# MB9AF12xL register map
File version: 1.0
CPU: 
Registers are 8-bit, read-write, reset 0x0 unless marked. A register's access mark holds for its fields unless they carry their own. Offsets are from the block's base; lines under a group give offsets from that group; [hi:lo] are bit positions; {n}, {i} and the like mark numbered series; 'fields as' and 'values as' point back to an identical list; <NAME> marks a mode.

## Memory map
0x40000000 FLASH_IF blocks up to offset 0xC — peripheral FLASH_IF
0x40000200 UNIQUE_ID size 0x4 — peripheral UNIQUE_ID
0x40010000 CRG size 0x1 — peripheral CRG
0x40011000 HWWDT size 0x4 — peripheral HWWDT
0x40012000 SWWDT size 0x4 — peripheral SWWDT
0x40015000 DTIM size 0x1C — peripheral DTIM
0x40020000 MFT0 size 0x2 — peripheral MFT0
0x40024000 MFT_PPG size 0x2 — peripheral MFT_PPG
0x40025000 BT0 size 0x2 — peripheral BT0
0x40025040 BT1 size 0x2 — peripheral BT0
0x40025080 BT2 size 0x2 — peripheral BT0
0x400250C0 BT3 size 0x2 — peripheral BT0
0x40025100 BTIOSEL03 size 0x2 — peripheral BTIOSEL03
0x40025200 BT4 size 0x2 — peripheral BT0
0x40025240 BT5 size 0x2 — peripheral BT0
0x40025280 BT6 size 0x2 — peripheral BT0
0x400252C0 BT7 size 0x2 — peripheral BT0
0x40025300 BTIOSEL47 size 0x2 — peripheral BTIOSEL47
0x40025F00 SBSSR blocks up to offset 0xFE — peripheral SBSSR
0x40027000 ADC0 size 0x2 — peripheral ADC0
0x40028000 DAC size 0x3 — peripheral DAC
0x4002E000 CRTRIM size 0x1 — peripheral CRTRIM
0x40030000 EXTI size 0x4 — peripheral EXTI
0x40031000 INTREQ size 0x4 — peripheral INTREQ
0x40033000 GPIO size 0x740 — peripheral GPIO
0x40035000 LVD size 0x2 — peripheral LVD
0x40035100 DS size 0x1 — peripheral DS
0x40038000 MFS0 size 0x2 — peripheral MFS0
0x40038100 MFS1 size 0x2 — peripheral MFS0
0x40038300 MFS3 size 0x2 — peripheral MFS0
0x40038500 MFS5 size 0x2 — peripheral MFS0
0x4003B000 RTC size 0x13 — peripheral RTC

## Interrupts
0 CSV (CRG)
1 SWDT (SWWDT)
2 LVD
3 WFG (MFT0)
4 EXTINT0_7 (EXTI)
5 EXTINT8_23 (EXTI)
6 DTIM_QDU (DTIM)
7 MFS0RX (MFS0)
8 MFS0TX (MFS0)
9 MFS1RX (MFS1)
10 MFS1TX (MFS1)
13 MFS3RX (MFS3)
14 MFS3TX (MFS3)
17 MFS5RX (MFS5)
18 MFS5TX (MFS5)
23 PPG (MFT_PPG)
24 OSC_PLL_WC (CRG)
25 ADC0
28 FRTIM (MFT0)
29 INCAP (MFT0)
30 OUTCOMP (MFT0)
31 BTIM0_7 (BT{n} (n=0..7))

## FLASH_IF — peripheral FLASH_IF
Base 0x40000000
0x04 FRWTR 32-bit reset 0x2
  [1:0] RWT
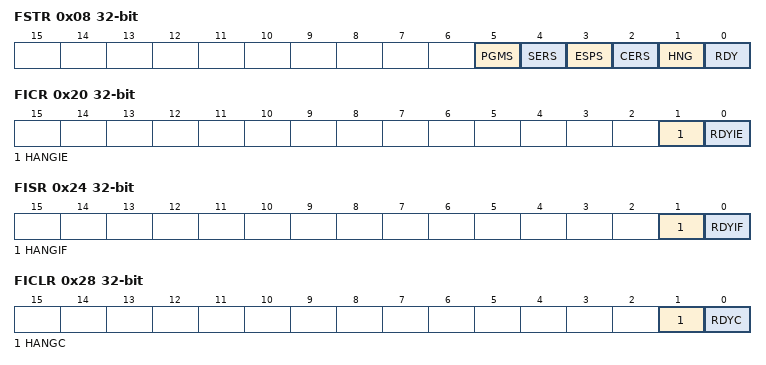
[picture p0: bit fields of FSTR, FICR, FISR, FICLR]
0x08 FSTR 32-bit ro
  [5] PGMS, [4] SERS, [3] ESPS, [2] CERS, [1] HNG, [0] RDY
0x20 FICR 32-bit
  [1] HANGIE, [0] RDYIE
0x24 FISR 32-bit
  [1] HANGIF, [0] RDYIF
0x28 FICLR 32-bit wo
  [1] HANGC rw, [0] RDYC rw
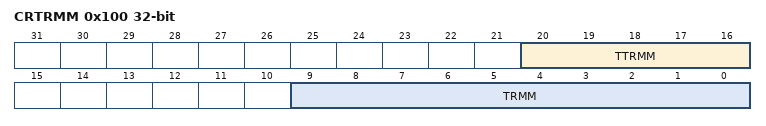
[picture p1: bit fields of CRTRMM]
0x100 CRTRMM 32-bit ro reset not defined
  [20:16] TTRMM, [9:0] TRMM

## UNIQUE_ID — peripheral UNIQUE_ID
Base 0x40000200
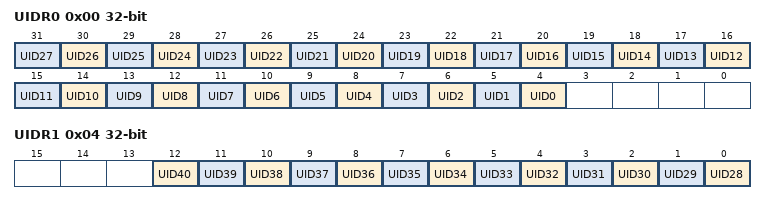
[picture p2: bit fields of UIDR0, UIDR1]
0x00 UIDR0 32-bit ro
  [n+4] UID{n} (n=0..27)
0x04 UIDR1 32-bit ro
  [n-28] UID{n} (n=28..40)

## CRG — peripheral CRG
Base 0x40010000
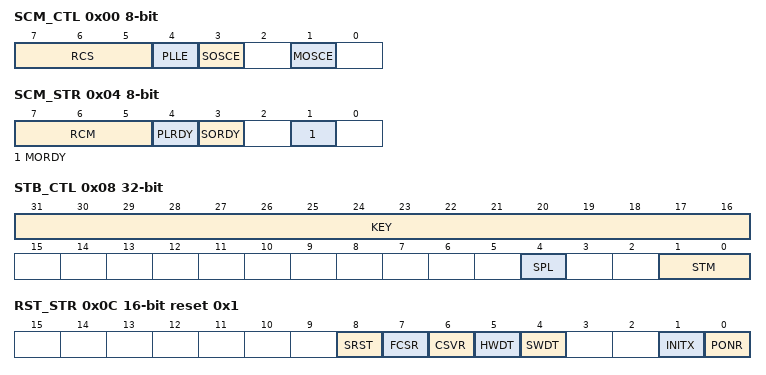
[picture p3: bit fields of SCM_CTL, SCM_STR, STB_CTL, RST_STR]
0x00 SCM_CTL
  [7:5] RCS, [4] PLLE, [3] SOSCE, [1] MOSCE
0x04 SCM_STR ro
  [7:5] RCM, [4] PLRDY, [3] SORDY, [1] MORDY
0x08 STB_CTL 32-bit
  [31:16] KEY, [4] SPL, [1:0] STM
0x0C RST_STR 16-bit ro reset 0x1
  [8] SRST, [7] FCSR, [6] CSVR, [5] HWDT, [4] SWDT, [1] INITX, [0] PONR
0x10 BSC_PSR
  [2:0] BSR
0x14 APBC0_PSR
  [1:0] APBC0
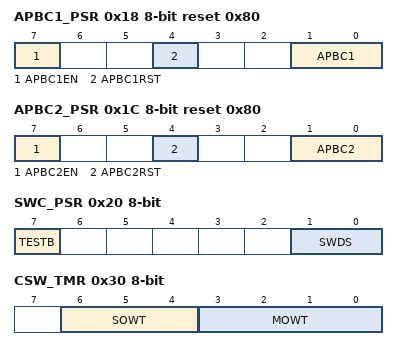
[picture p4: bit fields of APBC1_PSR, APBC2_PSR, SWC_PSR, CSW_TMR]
0x18 APBC1_PSR reset 0x80
  [7] APBC1EN, [4] APBC1RST, [1:0] APBC1
0x1C APBC2_PSR reset 0x80
  [7] APBC2EN, [4] APBC2RST, [1:0] APBC2
0x20 SWC_PSR (reset mask 0x3)
  [7] TESTB, [1:0] SWDS
0x28 TTC_PSR
  [1:0] TTC
0x30 CSW_TMR
  [6:4] SOWT, [3:0] MOWT
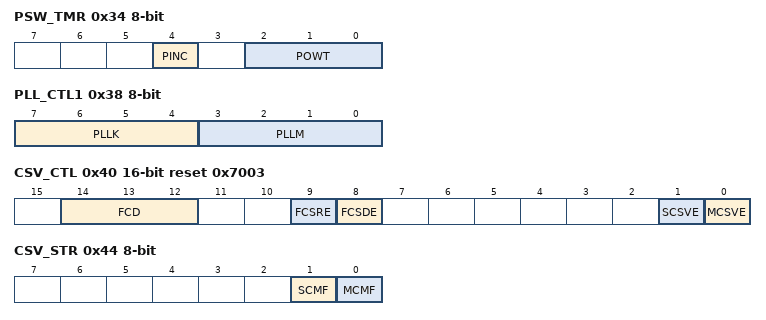
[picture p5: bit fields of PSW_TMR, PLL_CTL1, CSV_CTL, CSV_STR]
0x34 PSW_TMR
  [4] PINC, [2:0] POWT
0x38 PLL_CTL1
  [7:4] PLLK, [3:0] PLLM
0x3C PLL_CTL2
  [5:0] PLLN
0x40 CSV_CTL 16-bit reset 0x7003
  [14:12] FCD, [9] FCSRE, [8] FCSDE, [1] SCSVE, [0] MCSVE
0x44 CSV_STR ro
  [1] SCMF, [0] MCMF
0x48 FCSWH_CTL 16-bit reset 0xFFFF
0x4C FCSWL_CTL 16-bit
0x50 FCSWD_CTL 16-bit ro
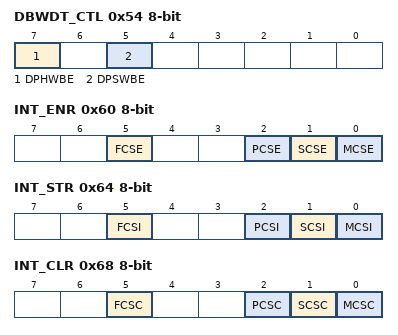
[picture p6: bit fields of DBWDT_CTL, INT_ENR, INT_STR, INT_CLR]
0x54 DBWDT_CTL
  [7] DPHWBE, [5] DPSWBE
0x60 INT_ENR
  [5] FCSE, [2] PCSE, [1] SCSE, [0] MCSE
0x64 INT_STR ro
  [5] FCSI, [2] PCSI, [1] SCSI, [0] MCSI
0x68 INT_CLR wo
  [5] FCSC, [2] PCSC, [1] SCSC, [0] MCSC

## CRTRIM — peripheral CRTRIM
Base 0x4002E000
0x00 MCR_PSR reset 0x1
  [1:0] CSR
0x04 MCR_FTRM 16-bit reset 0x200
  [9:0] TRD
0x08 MCR_TTRM reset 0xF
  [4:0] TRT
0x0C MCR_RLR 32-bit reset 0x1
  [31:0] TRMLCK
